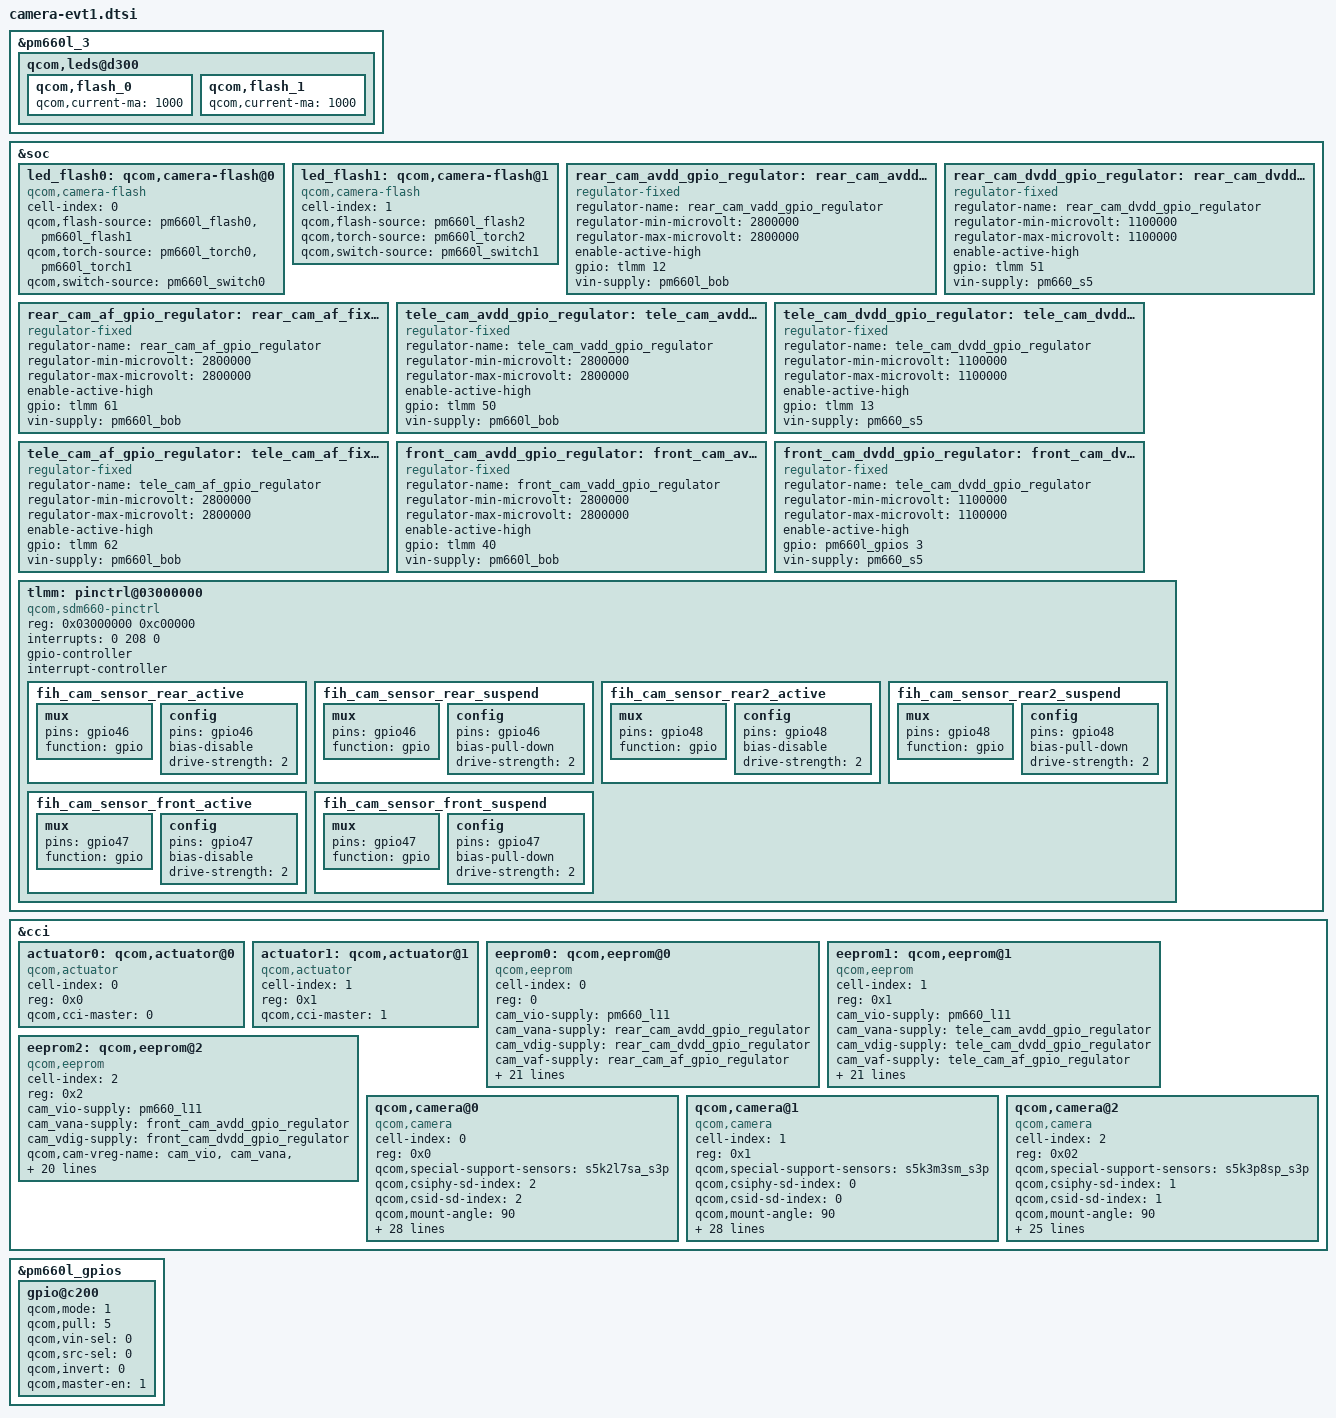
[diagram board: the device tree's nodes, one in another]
/*
 * Copyright (c) 2016, The Linux Foundation. All rights reserved.
 *
 * This program is free software; you can redistribute it and/or modify
 * it under the terms of the GNU General Public License version 2 and
 * only version 2 as published by the Free Software Foundation.
 *
 * This program is distributed in the hope that it will be useful,
 * but WITHOUT ANY WARRANTY; without even the implied warranty of
 * MERCHANTABILITY or FITNESS FOR A PARTICULAR PURPOSE.  See the
 * GNU General Public License for more details.
 */
&pm660l_3 {
	qcom,leds@d300 {
		qcom,flash_0 {
			qcom,current-ma = <1000>;
		};

		qcom,flash_1 {
			qcom,current-ma = <1000>;
		};
	};
};

&soc {
	led_flash0: qcom,camera-flash@0 {
		cell-index = <0>;
		compatible = "qcom,camera-flash";
		qcom,flash-source = <&pm660l_flash0 &pm660l_flash1>;
		qcom,torch-source = <&pm660l_torch0 &pm660l_torch1>;
		qcom,switch-source = <&pm660l_switch0>;
		status = "ok";
	};

	led_flash1: qcom,camera-flash@1 {
		cell-index = <1>;
		compatible = "qcom,camera-flash";
		qcom,flash-source = <&pm660l_flash2>;
		qcom,torch-source = <&pm660l_torch2>;
		qcom,switch-source = <&pm660l_switch1>;
		status = "ok";
	};
//Main Wide
	rear_cam_avdd_gpio_regulator: rear_cam_avdd_fixed_regulator {
		compatible = "regulator-fixed";
		regulator-name = "rear_cam_vadd_gpio_regulator";
		regulator-min-microvolt = <2800000>;
		regulator-max-microvolt = <2800000>;
		enable-active-high;
		gpio = <&tlmm 12 0>;
		vin-supply = <&pm660l_bob>;
	};
	rear_cam_dvdd_gpio_regulator: rear_cam_dvdd_fixed_regulator {
		compatible = "regulator-fixed";
		regulator-name = "rear_cam_dvdd_gpio_regulator";
		regulator-min-microvolt = <1100000>;
		regulator-max-microvolt = <1100000>;
		enable-active-high;
    gpio = <&tlmm 51 0>;
		vin-supply = <&pm660_s5>;
	};
	rear_cam_af_gpio_regulator: rear_cam_af_fixed_regulator {
		compatible = "regulator-fixed";
		regulator-name = "rear_cam_af_gpio_regulator";
		regulator-min-microvolt = <2800000>;
		regulator-max-microvolt = <2800000>;
		enable-active-high;
		gpio = <&tlmm 61 0>;
		vin-supply = <&pm660l_bob>;
	};
//Main Tele
	tele_cam_avdd_gpio_regulator: tele_cam_avdd_fixed_regulator {
		compatible = "regulator-fixed";
		regulator-name = "tele_cam_vadd_gpio_regulator";
		regulator-min-microvolt = <2800000>;
		regulator-max-microvolt = <2800000>;
		enable-active-high;
		gpio = <&tlmm 50 0>;
		vin-supply = <&pm660l_bob>;
	};
	tele_cam_dvdd_gpio_regulator: tele_cam_dvdd_fixed_regulator {
		compatible = "regulator-fixed";
		regulator-name = "tele_cam_dvdd_gpio_regulator";
		regulator-min-microvolt = <1100000>;
		regulator-max-microvolt = <1100000>;
		enable-active-high;
    gpio = <&tlmm 13 0>;
		vin-supply = <&pm660_s5>;
	};
	tele_cam_af_gpio_regulator: tele_cam_af_fixed_regulator {
		compatible = "regulator-fixed";
		regulator-name = "tele_cam_af_gpio_regulator";
		regulator-min-microvolt = <2800000>;
		regulator-max-microvolt = <2800000>;
		enable-active-high;
		gpio = <&tlmm 62 0>;
		vin-supply = <&pm660l_bob>;
	};
//front
	front_cam_avdd_gpio_regulator: front_cam_avdd_fixed_regulator {
		compatible = "regulator-fixed";
		regulator-name = "front_cam_vadd_gpio_regulator";
		regulator-min-microvolt = <2800000>;
		regulator-max-microvolt = <2800000>;
		enable-active-high;
		gpio = <&tlmm 40 0>;
		vin-supply = <&pm660l_bob>;
	};
	front_cam_dvdd_gpio_regulator: front_cam_dvdd_fixed_regulator {
		compatible = "regulator-fixed";
		regulator-name = "tele_cam_dvdd_gpio_regulator";
		regulator-min-microvolt = <1100000>;
		regulator-max-microvolt = <1100000>;
		enable-active-high;
    gpio = <&pm660l_gpios 3 0>;
		vin-supply = <&pm660_s5>;
	};

	tlmm: pinctrl@03000000 {
		compatible = "qcom,sdm660-pinctrl";
		reg = <0x03000000 0xc00000>;
		interrupts = <0 208 0>;
		gpio-controller;
		#gpio-cells = <2>;
		interrupt-controller;
		#interrupt-cells = <2>;

		fih_cam_sensor_rear_active: fih_cam_sensor_rear_active {
			/* RESET */
			mux {
				pins = "gpio46";
				function = "gpio";
			};

			config {
				pins = "gpio46";
				bias-disable; /* No PULL */
				drive-strength = <2>; /* 2 MA */
			};
		};

		fih_cam_sensor_rear_suspend: fih_cam_sensor_rear_suspend {
			/* RESET */
			mux {
				pins = "gpio46";
				function = "gpio";
			};

			config {
				pins = "gpio46";
				bias-pull-down; /* PULL DOWN */
				drive-strength = <2>; /* 2 MA */
			};
		};
		fih_cam_sensor_rear2_active: fih_cam_sensor_rear2_active {
				/* RESET */
				mux {
					pins = "gpio48";
					function = "gpio";
				};

				config {
					pins = "gpio48";
					bias-disable; /* No PULL */
					drive-strength = <2>; /* 2 MA */
				};
			};

		fih_cam_sensor_rear2_suspend: fih_cam_sensor_rear2_suspend {
			/* RESET */
			mux {
				pins = "gpio48";
				function = "gpio";
			};

			config {
				pins = "gpio48";
				bias-pull-down; /* PULL DOWN */
				drive-strength = <2>; /* 2 MA */
			};
		};

		fih_cam_sensor_front_active: fih_cam_sensor_front_active {
			/* RESET */
			mux {
				pins = "gpio47";
				function = "gpio";
			};

			config {
				pins = "gpio47";
				bias-disable; /* No PULL */
				drive-strength = <2>; /* 2 MA */
			};
		};

		fih_cam_sensor_front_suspend: fih_cam_sensor_front_suspend {
			/* RESET */
			mux {
				pins = "gpio47";
				function = "gpio";
			};

			config {
				pins = "gpio47";
				bias-pull-down; /* PULL DOWN */
				drive-strength = <2>; /* 2 MA */
			};
		};
	};
};

/* CCI portion*/
&cci {
		/delete-node/qcom,camera@0;
		/delete-node/qcom,camera@1;
		/delete-node/qcom,camera@2;
		/delete-node/qcom,camera@3;
		/delete-node/qcom,eeprom@0;
		/delete-node/qcom,eeprom@1;
		/delete-node/qcom,eeprom@2;
		/delete-node/qcom,actuator@0;
		/delete-node/qcom,actuator@1;
		/delete-node/qcom,actuator@2;
		/delete-node/qcom,ois@0;
};

&cci {

	actuator0: qcom,actuator@0 {
		cell-index = <0>;
		reg = <0x0>;
		compatible = "qcom,actuator";
		qcom,cci-master = <0>;
	};

	actuator1: qcom,actuator@1 {
		cell-index = <1>;
		reg = <0x1>;
		compatible = "qcom,actuator";
		qcom,cci-master = <1>;
	};

	eeprom0: qcom,eeprom@0 {
		cell-index = <0>;
		reg = <0>;
		compatible = "qcom,eeprom";
		cam_vio-supply = <&pm660_l11>;
		cam_vana-supply = <&rear_cam_avdd_gpio_regulator>;
		cam_vdig-supply = <&rear_cam_dvdd_gpio_regulator>;
		cam_vaf-supply = <&rear_cam_af_gpio_regulator>;
		qcom,cam-vreg-name = "cam_vio", "cam_vana", "cam_vdig", "cam_vaf";
		qcom,cam-vreg-min-voltage = <1780000 0 0 2800000>;
		qcom,cam-vreg-max-voltage = <1950000 0 0 2800000>;
		qcom,cam-vreg-op-mode = <105000 0 0 80000>;
		qcom,gpio-no-mux = <0>;
		pinctrl-names = "cam_default", "cam_suspend";
		pinctrl-0 = <&cam_sensor_mclk0_active
				 &fih_cam_sensor_rear_active>;
		pinctrl-1 = <&cam_sensor_mclk0_suspend
				 &fih_cam_sensor_rear_suspend>;
		gpios = <&tlmm 32 0>,
			<&tlmm 46 0>;
		qcom,gpio-reset = <1>;
		qcom,gpio-req-tbl-num = <0 1>;
		qcom,gpio-req-tbl-flags = <1 0>;
		qcom,gpio-req-tbl-label = "CAMIF_MCLK",
					"CAM_RESET";
		qcom,sensor-position = <0>;
		qcom,sensor-mode = <0>;
		qcom,cci-master = <0>;
		status = "ok";
		clocks = <&clock_mmss MCLK0_CLK_SRC>,
				<&clock_mmss MMSS_CAMSS_MCLK0_CLK>;
		clock-names = "cam_src_clk", "cam_clk";
		qcom,clock-rates = <24000000 0>;
	};

	eeprom1: qcom,eeprom@1 {
		cell-index = <1>;
		reg = <0x1>;
		compatible = "qcom,eeprom";
		cam_vio-supply = <&pm660_l11>;
		cam_vana-supply = <&tele_cam_avdd_gpio_regulator>;
		cam_vdig-supply = <&tele_cam_dvdd_gpio_regulator>;
		cam_vaf-supply = <&tele_cam_af_gpio_regulator>;
		qcom,cam-vreg-name = "cam_vio", "cam_vana", "cam_vdig", "cam_vaf";
		qcom,cam-vreg-min-voltage = <1780000 0 0 2800000>;
		qcom,cam-vreg-max-voltage = <1950000 0 0 2800000>;
		qcom,cam-vreg-op-mode = <105000 0 0 80000>;
		qcom,gpio-no-mux = <0>;
		pinctrl-names = "cam_default", "cam_suspend";
		pinctrl-0 = <&cam_sensor_mclk2_active
				 &fih_cam_sensor_rear2_active>;
		pinctrl-1 = <&cam_sensor_mclk2_suspend
				 &fih_cam_sensor_rear2_suspend>;
		gpios = <&tlmm 34 0>,
			<&tlmm 48 0>;
		qcom,gpio-reset = <1>;
		qcom,gpio-req-tbl-num = <0 1>;
		qcom,gpio-req-tbl-flags = <1 0>;
		qcom,gpio-req-tbl-label = "CAMIF_MCLK",
					"CAM_RESET";
		qcom,sensor-position = <0>;
		qcom,sensor-mode = <0>;
		qcom,cci-master = <1>;
		status = "ok";
		clocks = <&clock_mmss MCLK2_CLK_SRC>,
			<&clock_mmss MMSS_CAMSS_MCLK2_CLK>;
		clock-names = "cam_src_clk", "cam_clk";
		qcom,clock-rates = <24000000 0>;
	};

	eeprom2: qcom,eeprom@2 {
		cell-index = <2>;
		reg = <0x2>;
		compatible = "qcom,eeprom";
		cam_vio-supply = <&pm660_l11>;
		cam_vana-supply = <&front_cam_avdd_gpio_regulator>;
		cam_vdig-supply = <&front_cam_dvdd_gpio_regulator>;
		qcom,cam-vreg-name = "cam_vio", "cam_vana", "cam_vdig";
		qcom,cam-vreg-min-voltage = <1780000 0 0 >;
		qcom,cam-vreg-max-voltage = <1950000 0 0 >;
		qcom,cam-vreg-op-mode = <105000 0 0 >;
		qcom,gpio-no-mux = <0>;
		pinctrl-names = "cam_default", "cam_suspend";
		pinctrl-0 = <&cam_sensor_mclk1_active
				 &fih_cam_sensor_front_active>;
		pinctrl-1 = <&cam_sensor_mclk1_suspend
				 &fih_cam_sensor_front_suspend>;
		gpios = <&tlmm 33 0>,
			<&tlmm 47 0>;
		qcom,gpio-reset = <1>;
		qcom,gpio-req-tbl-num = <0 1>;
		qcom,gpio-req-tbl-flags = <1 0>;
		qcom,gpio-req-tbl-label = "CAMIF_MCLK",
					"CAM_RESET";
		qcom,sensor-position = <1>;
		qcom,sensor-mode = <0>;
		qcom,cci-master = <1>;
		status = "ok";
		clocks = <&clock_mmss MCLK1_CLK_SRC>,
			<&clock_mmss MMSS_CAMSS_MCLK1_CLK>;
		clock-names = "cam_src_clk", "cam_clk";
		qcom,clock-rates = <24000000 0>;
	};


	qcom,camera@0 { //wide
		cell-index = <0>;
		compatible = "qcom,camera";
		reg = <0x0>;
		qcom,special-support-sensors = "s5k2l7sa_s3p";
		qcom,csiphy-sd-index = <2>;
		qcom,csid-sd-index = <2>;
		qcom,mount-angle = <90>;
		qcom,led-flash-src = <&led_flash0>;
		qcom,actuator-src = <&actuator0>;
		qcom,eeprom-src = <&eeprom0>;
		cam_vio-supply = <&pm660_l11>;
		cam_vana-supply = <&rear_cam_avdd_gpio_regulator>;
		cam_vdig-supply = <&rear_cam_dvdd_gpio_regulator>;
		cam_vaf-supply = <&rear_cam_af_gpio_regulator>;
		qcom,cam-vreg-name = "cam_vio", "cam_vana", "cam_vdig", "cam_vaf";
		qcom,cam-vreg-min-voltage = <1780000 0 0 2800000>;
		qcom,cam-vreg-max-voltage = <1950000 0 0 2800000>;
		qcom,cam-vreg-op-mode = <105000 0 0 80000>;
		qcom,gpio-no-mux = <0>;
		pinctrl-names = "cam_default", "cam_suspend";
		pinctrl-0 = <&cam_sensor_mclk0_active
				 &fih_cam_sensor_rear_active>;
		pinctrl-1 = <&cam_sensor_mclk0_suspend
				 &fih_cam_sensor_rear_suspend>;
		gpios = <&tlmm 32 0>,
			<&tlmm 46 0>;
		qcom,gpio-reset = <1>;
		qcom,gpio-req-tbl-num = <0 1>;
		qcom,gpio-req-tbl-flags = <1 0>;
		qcom,gpio-req-tbl-label = "CAMIF_MCLK",
					"CAM_RESET";
		qcom,sensor-position = <0>;
		qcom,sensor-mode = <0>;
		qcom,cci-master = <0>;
		status = "ok";
		clocks = <&clock_mmss MCLK0_CLK_SRC>,
				<&clock_mmss MMSS_CAMSS_MCLK0_CLK>;
		clock-names = "cam_src_clk", "cam_clk";
		qcom,clock-rates = <24000000 0>;
	};

	qcom,camera@1 {//tele
		cell-index = <1>;
		compatible = "qcom,camera";
		reg = <0x1>;
		qcom,special-support-sensors = "s5k3m3sm_s3p";
		qcom,csiphy-sd-index = <0>;
		qcom,csid-sd-index = <0>;
		qcom,mount-angle = <90>;
		qcom,led-flash-src = <&led_flash0>;
		qcom,actuator-src = <&actuator1>;
		qcom,eeprom-src = <&eeprom1>;
		cam_vio-supply = <&pm660_l11>;
		cam_vana-supply = <&tele_cam_avdd_gpio_regulator>;
		cam_vdig-supply = <&tele_cam_dvdd_gpio_regulator>;
		cam_vaf-supply = <&tele_cam_af_gpio_regulator>;
		qcom,cam-vreg-name = "cam_vio", "cam_vana", "cam_vdig", "cam_vaf";
		qcom,cam-vreg-min-voltage = <1780000 0 0 2800000>;
		qcom,cam-vreg-max-voltage = <1950000 0 0 2800000>;
		qcom,cam-vreg-op-mode = <105000 0 0 80000>;
		qcom,gpio-no-mux = <0>;
		pinctrl-names = "cam_default", "cam_suspend";
		pinctrl-0 = <&cam_sensor_mclk2_active
				 &fih_cam_sensor_rear2_active>;
		pinctrl-1 = <&cam_sensor_mclk2_suspend
				 &fih_cam_sensor_rear2_suspend>;
		gpios = <&tlmm 34 0>,
			<&tlmm 48 0>;
		qcom,gpio-reset = <1>;
		qcom,gpio-req-tbl-num = <0 1>;
		qcom,gpio-req-tbl-flags = <1 0>;
		qcom,gpio-req-tbl-label = "CAMIF_MCLK",
					"CAM_RESET";
		qcom,sensor-position = <0>;
		qcom,sensor-mode = <0>;
		qcom,cci-master = <1>;
		status = "ok";
		clocks = <&clock_mmss MCLK2_CLK_SRC>,
			<&clock_mmss MMSS_CAMSS_MCLK2_CLK>;
		clock-names = "cam_src_clk", "cam_clk";
		qcom,clock-rates = <24000000 0>;
	};

	qcom,camera@2 {//front
		cell-index = <2>;
		compatible = "qcom,camera";
		reg = <0x02>;
		qcom,special-support-sensors = "s5k3p8sp_s3p";
		qcom,csiphy-sd-index = <1>;
		qcom,csid-sd-index = <1>;
		qcom,mount-angle = <90>;
		qcom,eeprom-src = <&eeprom2>;
		cam_vio-supply = <&pm660_l11>;
		cam_vana-supply = <&front_cam_avdd_gpio_regulator>;
		cam_vdig-supply = <&front_cam_dvdd_gpio_regulator>;
		qcom,cam-vreg-name = "cam_vio", "cam_vana", "cam_vdig";
		qcom,cam-vreg-min-voltage = <1780000 0 0 >;
		qcom,cam-vreg-max-voltage = <1950000 0 0 >;
		qcom,cam-vreg-op-mode = <105000 0 0 >;
		qcom,gpio-no-mux = <0>;
		pinctrl-names = "cam_default", "cam_suspend";
		pinctrl-0 = <&cam_sensor_mclk1_active
				 &fih_cam_sensor_front_active>;
		pinctrl-1 = <&cam_sensor_mclk1_suspend
				 &fih_cam_sensor_front_suspend>;
		gpios = <&tlmm 33 0>,
			<&tlmm 47 0>;
		qcom,gpio-reset = <1>;
		qcom,gpio-req-tbl-num = <0 1>;
		qcom,gpio-req-tbl-flags = <1 0>;
		qcom,gpio-req-tbl-label = "CAMIF_MCLK",
					"CAM_RESET";
		qcom,sensor-position = <1>;
		qcom,sensor-mode = <0>;
		qcom,cci-master = <1>;
		status = "ok";
		clocks = <&clock_mmss MCLK1_CLK_SRC>,
			<&clock_mmss MMSS_CAMSS_MCLK1_CLK>;
		clock-names = "cam_src_clk", "cam_clk";
		qcom,clock-rates = <24000000 0>;
	};
};

&pm660l_gpios {
	gpio@c200 { /* GPIO3 -CAMERA SENSOR 2 VDIG*/
		qcom,mode = <1>;                /* Output */
		qcom,pull = <5>;                /* No Pull */
		qcom,vin-sel = <0>;             /* VIN1 GPIO_LV */
		qcom,src-sel = <0>;             /* GPIO */
		qcom,invert = <0>;              /* Invert */
		qcom,master-en = <1>;           /* Enable GPIO */
		status = "ok";
	};
};
